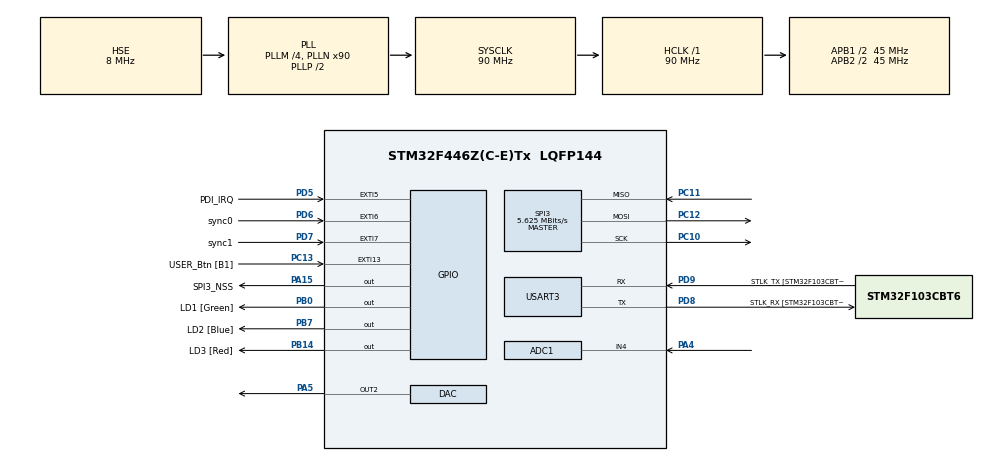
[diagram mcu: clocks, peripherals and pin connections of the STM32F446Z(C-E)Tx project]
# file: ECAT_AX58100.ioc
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ADC1.Channel-0\#ChannelRegularConversion=ADC_CHANNEL_4
ADC1.ContinuousConvMode=ENABLE
ADC1.NbrOfConversionFlag=1
ADC1.Rank-0\#ChannelRegularConversion=1
ADC1.SamplingTime-0\#ChannelRegularConversion=ADC_SAMPLETIME_144CYCLES
ADC1.master=1
Dma.ADC1.0.Direction=DMA_PERIPH_TO_MEMORY
Dma.ADC1.0.FIFOMode=DMA_FIFOMODE_DISABLE
Dma.ADC1.0.Instance=DMA2_Stream0
Dma.ADC1.0.MemDataAlignment=DMA_MDATAALIGN_HALFWORD
Dma.ADC1.0.MemInc=DMA_MINC_ENABLE
Dma.ADC1.0.Mode=DMA_NORMAL
Dma.ADC1.0.PeriphDataAlignment=DMA_PDATAALIGN_HALFWORD
Dma.ADC1.0.PeriphInc=DMA_PINC_DISABLE
Dma.ADC1.0.Priority=DMA_PRIORITY_LOW
Dma.Request0=ADC1
Mcu.Family=STM32F4
Mcu.Name=STM32F446Z(C-E)Tx
Mcu.Package=LQFP144
NVIC.DMA2_Stream0_IRQn=true\:0\:0\:false\:false\:true\:false\:true\:true
NVIC.EXTI15_10_IRQn=true\:0\:0\:false\:false\:true\:true\:true\:true
NVIC.EXTI9_5_IRQn=true\:0\:0\:false\:false\:true\:true\:true\:true
NVIC.PriorityGroup=NVIC_PRIORITYGROUP_4
NVIC.TIM6_DAC_IRQn=true\:0\:0\:false\:false\:true\:true\:true\:true
PA13.GPIO_Label=TMS
PA13.Mode=Serial_Wire
PA13.Signal=SYS_JTMS-SWDIO
PA14.GPIO_Label=TCK
PA14.Mode=Serial_Wire
PA14.Signal=SYS_JTCK-SWCLK
PA15.GPIO_Label=SPI3_NSS
PA15.PinState=GPIO_PIN_SET
PA15.Signal=GPIO_Output
PA4.Signal=ADCx_IN4
PA5.Signal=COMP_DAC2_group
PB0.GPIO_Label=LD1 [Green]
PB0.Signal=GPIO_Output
PB14.GPIO_Label=LD3 [Red]
PB14.Signal=GPIO_Output
PB7.GPIO_Label=LD2 [Blue]
PB7.Signal=GPIO_Output
PC10.Mode=Full_Duplex_Master
PC10.Signal=SPI3_SCK
PC11.Mode=Full_Duplex_Master
PC11.Signal=SPI3_MISO
PC12.Mode=Full_Duplex_Master
PC12.Signal=SPI3_MOSI
PC13.GPIO_Label=USER_Btn [B1]
PC13.Signal=GPXTI13
PD5.GPIO_Label=PDI_IRQ
PD5.GPIO_ModeDefaultEXTI=GPIO_MODE_IT_FALLING
PD5.Signal=GPXTI5
PD6.GPIO_Label=sync0
PD6.GPIO_ModeDefaultEXTI=GPIO_MODE_IT_FALLING
PD6.Signal=GPXTI6
PD7.GPIO_Label=sync1
PD7.GPIO_ModeDefaultEXTI=GPIO_MODE_IT_FALLING
PD7.Signal=GPXTI7
PD8.GPIO_Label=STLK_RX [STM32F103CBT6_PA3]
PD8.Mode=Asynchronous
PD8.Signal=USART3_TX
PD9.GPIO_Label=STLK_TX [STM32F103CBT6_PA2]
PD9.Mode=Asynchronous
PD9.Signal=USART3_RX
PH0-OSC_IN.GPIO_Label=MCO [STM32F103CBT6_PA8]
PH0-OSC_IN.Mode=HSE-External-Oscillator
PH0-OSC_IN.Signal=RCC_OSC_IN
PH1-OSC_OUT.Mode=HSE-External-Oscillator
PH1-OSC_OUT.Signal=RCC_OSC_OUT
ProjectManager.HeapSize=0x800
ProjectManager.StackSize=0xB00
ProjectManager.TargetToolchain=STM32CubeIDE
RCC.48MHZClocksFreq_Value=24000000
RCC.AHBFreq_Value=90000000
RCC.APB1CLKDivider=RCC_HCLK_DIV2
RCC.APB1Freq_Value=45000000
RCC.APB1TimFreq_Value=90000000
RCC.APB2CLKDivider=RCC_HCLK_DIV2
RCC.APB2Freq_Value=45000000
RCC.APB2TimFreq_Value=90000000
RCC.CortexFreq_Value=90000000
RCC.HCLKFreq_Value=90000000
RCC.HSE_VALUE=8000000
RCC.HSI_VALUE=16000000
RCC.PLLM=4
RCC.PLLMUL=RCC_PLL_MUL9
RCC.PLLN=90
RCC.PLLQ=7
RCC.PLLSourceVirtual=RCC_PLLSOURCE_HSE
RCC.PRESCALERUSB=RCC_USBCLKSOURCE_PLL_DIV1_5
RCC.SYSCLKFreq_VALUE=90000000
RCC.SYSCLKSource=RCC_SYSCLKSOURCE_PLLCLK
RCC.SYSCLKSourceVirtual=RCC_SYSCLKSOURCE_PLLCLK
RCC.USBFreq_Value=25714285.714285713
RCC.VCOOutputFreq_Value=180000000
SH.ADCx_IN4.0=ADC1_IN4,IN4
SH.COMP_DAC2_group.0=DAC_OUT2,DAC_OUT2
SPI3.BaudRatePrescaler=SPI_BAUDRATEPRESCALER_8
SPI3.CLKPhase=SPI_PHASE_2EDGE
SPI3.CLKPolarity=SPI_POLARITY_HIGH
SPI3.CalculateBaudRate=5.625 MBits/s
SPI3.DataSize=SPI_DATASIZE_8BIT
SPI3.Direction=SPI_DIRECTION_2LINES
SPI3.Mode=SPI_MODE_MASTER
SPI3.VirtualType=VM_MASTER
TIM6.AutoReloadPreload=TIM_AUTORELOAD_PRELOAD_ENABLE
TIM6.Period=1000-1
TIM6.Prescaler=90-1
USART3.VirtualMode=VM_ASYNC
VP_TIM6_VS_ClockSourceINT.Mode=Enable_Timer
board=NUCLEO-F446ZE

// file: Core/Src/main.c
/* USER CODE BEGIN Header */
/**
  ******************************************************************************
  * @file           : main.c
  * @brief          : Main program body
  ******************************************************************************
  * @attention
  *
  * Copyright (c) 2023 STMicroelectronics.
  * All rights reserved.
  *
  * This software is licensed under terms that can be found in the LICENSE file
  * in the root directory of this software component.
  * If no LICENSE file comes with this software, it is provided AS-IS.
  *
  ******************************************************************************
  */
/* USER CODE END Header */
#include "main.h"
#include "adc.h"
#include "dac.h"
#include "dma.h"
#include "spi.h"
#include "tim.h"
#include "usart.h"
#include "gpio.h"

/* USER CODE BEGIN Includes */
#include	<ssc_bsp.h>
#include	<el9800hw.h>
/* USER CODE END Includes */

void SystemClock_Config(void);

int main(void)
{

  /* MCU Configuration--------------------------------------------------------*/

  /* Reset of all peripherals, Initializes the Flash interface and the Systick. */
  HAL_Init();

  /* Configure the system clock */
  SystemClock_Config();

  /* Initialize all configured peripherals */
  MX_GPIO_Init();
  MX_SPI3_Init();
  MX_DMA_Init();
  MX_USART3_UART_Init();
  MX_ADC1_Init();
  MX_TIM6_Init();
  MX_DAC_Init();
  /* USER CODE BEGIN 2 */
  HW_Init();
  MainInit();

  ADC_Start_DMA();
  HAL_DAC_Start(&hdac, DAC_CHANNEL_2);
  /* USER CODE END 2 */

  /* Infinite loop */
  /* USER CODE BEGIN WHILE */
  while (1)
  {
	  MainLoop();
	  //HAL_Delay(500);
	  static int cntMainLoop = 0;
	  if (cntMainLoop == 10000)
	  {
//		  cntMainLoop = 0;
//		  HAL_GPIO_TogglePin(LD3_GPIO_Port, LD3_Pin);
	  }
	  cntMainLoop++;
    /* USER CODE END WHILE */

  }
}

void SystemClock_Config(void)
{
  RCC_OscInitTypeDef RCC_OscInitStruct = {0};
  RCC_ClkInitTypeDef RCC_ClkInitStruct = {0};

  /** Configure the main internal regulator output voltage
  */
  __HAL_RCC_PWR_CLK_ENABLE();
  __HAL_PWR_VOLTAGESCALING_CONFIG(PWR_REGULATOR_VOLTAGE_SCALE3);

  /** Initializes the RCC Oscillators according to the specified parameters
  * in the RCC_OscInitTypeDef structure.
  */
  RCC_OscInitStruct.OscillatorType = RCC_OSCILLATORTYPE_HSE;
  RCC_OscInitStruct.HSEState = RCC_HSE_ON;
  RCC_OscInitStruct.PLL.PLLState = RCC_PLL_ON;
  RCC_OscInitStruct.PLL.PLLSource = RCC_PLLSOURCE_HSE;
  RCC_OscInitStruct.PLL.PLLM = 4;
  RCC_OscInitStruct.PLL.PLLN = 90;
  RCC_OscInitStruct.PLL.PLLP = RCC_PLLP_DIV2;
  RCC_OscInitStruct.PLL.PLLQ = 7;
  RCC_OscInitStruct.PLL.PLLR = 2;
  if (HAL_RCC_OscConfig(&RCC_OscInitStruct) != HAL_OK)
  {
    Error_Handler();
  }

  /** Initializes the CPU, AHB and APB buses clocks
  */
  RCC_ClkInitStruct.ClockType = RCC_CLOCKTYPE_HCLK|RCC_CLOCKTYPE_SYSCLK
                              |RCC_CLOCKTYPE_PCLK1|RCC_CLOCKTYPE_PCLK2;
  RCC_ClkInitStruct.SYSCLKSource = RCC_SYSCLKSOURCE_PLLCLK;
  RCC_ClkInitStruct.AHBCLKDivider = RCC_SYSCLK_DIV1;
  RCC_ClkInitStruct.APB1CLKDivider = RCC_HCLK_DIV2;
  RCC_ClkInitStruct.APB2CLKDivider = RCC_HCLK_DIV2;

  if (HAL_RCC_ClockConfig(&RCC_ClkInitStruct, FLASH_LATENCY_2) != HAL_OK)
  {
    Error_Handler();
  }
}

void Error_Handler(void)
{
  __disable_irq();
  while (1)
  {
  }
}
